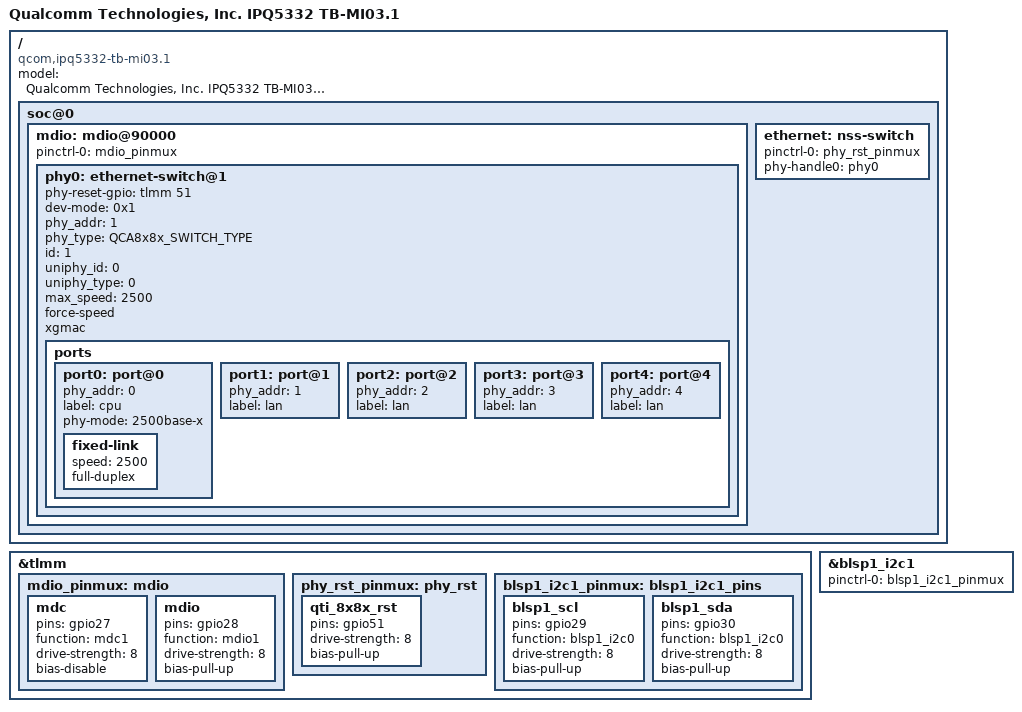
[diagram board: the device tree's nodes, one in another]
// SPDX-License-Identifier: GPL-2.0-only
/*
 * Copyright (c) Qualcomm Technologies, Inc. and/or its subsidiaries.
 */

/dts-v1/;

#include "ipq5332-rdp-common.dtsi"
#include "ipq5332-rdp-common-ub.dtsi"

/ {
	model = "Qualcomm Technologies, Inc. IPQ5332 TB-MI03.1";
	compatible = "qcom,ipq5332-tb-mi03.1", "qcom,ipq5332";

	soc@0 {
		mdio: mdio@90000 {
			pinctrl-names = "default";
			pinctrl-0 = <&mdio_pinmux>;
			status = "okay";

			phy0: ethernet-switch@1 {
				phy-reset-gpio = <&tlmm 51 0>;
				dev-mode = <0x1>;
				phy_addr = <1>;
				phy_type = <QCA8x8x_SWITCH_TYPE>;
				id = <1>;
				uniphy_id = <0>;
				uniphy_type = <0>;
				max_speed = <2500>;
				force-speed;
				xgmac;
				ports {
					#address-cells = <1>;
					#size-cells = <0>;

					port0: port@0 {
						phy_addr = <0>;
						label = "cpu";
						phy-mode = "2500base-x";
						fixed-link {
							speed = <2500>;
							full-duplex;
						};
					};

					port1: port@1 {
						phy_addr = <1>;
						label = "lan";
					};

					port2: port@2 {
						phy_addr = <2>;
						label = "lan";
					};

					port3: port@3 {
						phy_addr = <3>;
						label = "lan";
					};

					port4: port@4 {
						phy_addr = <4>;
						label = "lan";
					};
				};
			};

		};

		ethernet: nss-switch {
			pinctrl-names = "default";
			pinctrl-0 = <&phy_rst_pinmux>;
			phy-handle0 = <&phy0>;
			status = "okay";
		};
	};
};

&tlmm {
	mdio_pinmux: mdio {
		mdc {
			pins = "gpio27";
			function = "mdc1";
			drive-strength = <8>;
			bias-disable;
		};

		mdio {
			pins = "gpio28";
			function = "mdio1";
			drive-strength = <8>;
			bias-pull-up;
		};
	};

	phy_rst_pinmux: phy_rst {
		qti_8x8x_rst {
			pins = "gpio51";
			drive-strength = <8>;
			bias-pull-up;
		};
	};

	blsp1_i2c1_pinmux: blsp1_i2c1_pins {
		blsp1_scl {
			pins = "gpio29";
			function = "blsp1_i2c0";
			drive-strength = <8>;
			bias-pull-up;
		};

		blsp1_sda {
			pins = "gpio30";
			function = "blsp1_i2c0";
			drive-strength = <8>;
			bias-pull-up;
		};
	};
};

&blsp1_i2c1 {
	pinctrl-names = "default";
	pinctrl-0 = <&blsp1_i2c1_pinmux>;
	status = "okay";
};
